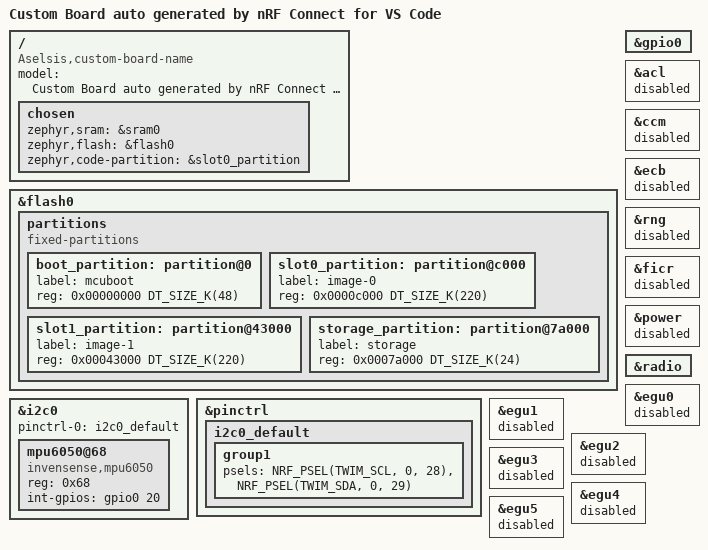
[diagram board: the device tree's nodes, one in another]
/dts-v1/;
#include <nordic/nrf52833_qdaa.dtsi>
#include "weaver_bike_nrf52833-pinctrl.dtsi"

/ {
	model = "Custom Board auto generated by nRF Connect for VS Code";
	compatible = "Aselsis,custom-board-name";

	chosen {
		zephyr,sram = &sram0;
		zephyr,flash = &flash0;
		zephyr,code-partition = &slot0_partition;
	};
};

&flash0 {
	partitions {
		compatible = "fixed-partitions";
		#address-cells = <1>;
		#size-cells = <1>;

		boot_partition: partition@0 {
			label = "mcuboot";
			reg = <0x00000000 DT_SIZE_K(48)>;
		};

		slot0_partition: partition@c000 {
			label = "image-0";
			reg = <0x0000c000 DT_SIZE_K(220)>;
		};

		slot1_partition: partition@43000 {
			label = "image-1";
			reg = <0x00043000 DT_SIZE_K(220)>;
		};

		storage_partition: partition@7a000 {
			label = "storage";
			reg = <0x0007a000 DT_SIZE_K(24)>;
		};
	};
};
&i2c0 {
	status = "okay";
	pinctrl-0 = <&i2c0_default>;
	pinctrl-names = "default";
	mpu6050@68 {
		compatible = "invensense,mpu6050";
		reg = <0x68>;
		int-gpios = <&gpio0 20 0>;
	};
};

&gpio0 {
	status = "okay";
};

&pinctrl {
	i2c0_default: i2c0_default {
		group1 {
			psels = <NRF_PSEL(TWIM_SCL, 0, 28)>, <NRF_PSEL(TWIM_SDA, 0, 29)>;
		};
	};
};

&acl {
	status = "disabled";
};

&ccm {
	status = "disabled";
};

&ecb {
	status = "disabled";
};

&rng {
	status = "disabled";
};

&ficr {
	status = "disabled";
};

&power {
	status = "disabled";
};

&radio {
	/delete-property/ dfe-supported;
	/delete-property/ ieee802154-supported;
	/delete-property/ ble-2mbps-supported;
	/delete-property/ ble-coded-phy-supported;
	/delete-property/ tx-high-power-supported;
};

&egu0 {
	status = "disabled";
};

&egu1 {
	status = "disabled";
};

&egu2 {
	status = "disabled";
};

&egu3 {
	status = "disabled";
};

&egu4 {
	status = "disabled";
};

&egu5 {
	status = "disabled";
};
